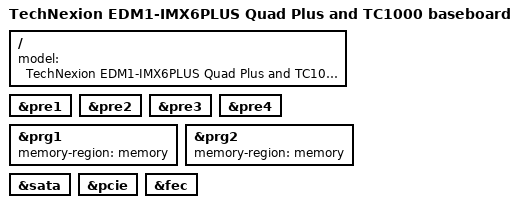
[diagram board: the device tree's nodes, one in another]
/*
 * Copyright 2017 Technexion Ltd.
 *
 * Author: Richard Hu <richard.hu@technexion.com>
 *	       Tapani Utriainen <tapani@technexion.com>
 *
 * The code contained herein is licensed under the GNU General Public
 * License. You may obtain a copy of the GNU General Public License
 * Version 2 or later at the following locations:
 *
 * http://www.opensource.org/licenses/gpl-license.html
 * http://www.gnu.org/copyleft/gpl.html
 */

#include "imx6q-edm1-cf-pmic_tc1000.dts"
#include "imx6qp.dtsi"

/ {
	model = "TechNexion EDM1-IMX6PLUS Quad Plus and TC1000 baseboard";
};

&pre1 {
	status = "okay";
};

&pre2 {
	status = "okay";
};

&pre3 {
	status = "okay";
};

&pre4 {
	status = "okay";
};

&prg1 {
	memory-region = <&memory>;
	status = "okay";
};

&prg2 {
	memory-region = <&memory>;
	status = "okay";
};

&sata {
	status = "okay";
};

&pcie {
	status = "okay";
};

&fec {
    /delete-property/ phy-reset-gpios;
};
